# nrf7120_enga_application register map
Vendor: Nordic Semiconductor; Series: nrf71; File version: 1
CPU: CM33 r0p4, little endian, MPU, FPU, 3 interrupt priority bits, 270 interrupts, 4 SAU regions
Registers are 32-bit, read-write, reset 0x0 unless marked. A register's access mark holds for its fields unless they carry their own. Offsets are from the block's base; [hi:lo] are bit positions; lines under a group give offsets from that group; 'fields as' and 'values as' point back to an identical list.

## CPUC_S — CPU control
Base 0xE0080000
0x100 EVENTS_FPUIOC — An invalid operation exception has occurred in the FPU.
  [0] EVENTS_FPUIOC
    0=NotGenerated (Event not generated); 1=Generated (Event generated)
0x104 EVENTS_FPUDZC — A floating-point divide-by-zero exception has occurred in the FPU.
  [0] EVENTS_FPUDZC
    values as EVENTS_FPUIOC.EVENTS_FPUIOC
0x108 EVENTS_FPUOFC — A floating-point overflow exception has occurred in the FPU.
  [0] EVENTS_FPUOFC
    values as EVENTS_FPUIOC.EVENTS_FPUIOC
0x10C EVENTS_FPUUFC — A floating-point underflow exception has occurred in the FPU.
  [0] EVENTS_FPUUFC
    values as EVENTS_FPUIOC.EVENTS_FPUIOC
0x110 EVENTS_FPUIXC — A floating-point inexact exception has occurred in the FPU.
  [0] EVENTS_FPUIXC
    values as EVENTS_FPUIOC.EVENTS_FPUIOC
0x114 EVENTS_FPUIDC — A floating-point input denormal exception has occurred in the FPU.
  [0] EVENTS_FPUIDC
    values as EVENTS_FPUIOC.EVENTS_FPUIOC
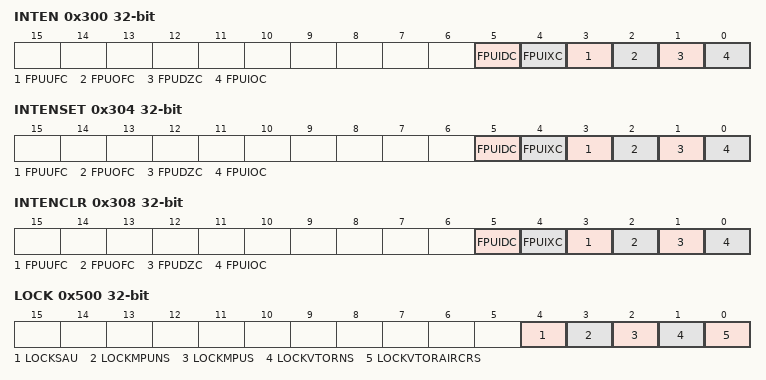
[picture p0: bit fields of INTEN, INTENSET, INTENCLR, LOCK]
0x300 INTEN — Enable or disable interrupt
  [all] fields
    0=Disabled; 1=Enabled
  [5] FPUIDC — Enable or disable interrupt for event FPUIDC
  [4] FPUIXC — Enable or disable interrupt for event FPUIXC
  [3] FPUUFC — Enable or disable interrupt for event FPUUFC
  [2] FPUOFC — Enable or disable interrupt for event FPUOFC
  [1] FPUDZC — Enable or disable interrupt for event FPUDZC
  [0] FPUIOC — Enable or disable interrupt for event FPUIOC
0x304 INTENSET — Enable interrupt
  [all] fields
    on read: 0=Disabled (Read: Disabled); 1=Enabled (Read: Enabled) | on write: 1=Set (Enable)
  [5] FPUIDC — Write '1' to enable interrupt for event FPUIDC
  [4] FPUIXC — Write '1' to enable interrupt for event FPUIXC
  [3] FPUUFC — Write '1' to enable interrupt for event FPUUFC
  [2] FPUOFC — Write '1' to enable interrupt for event FPUOFC
  [1] FPUDZC — Write '1' to enable interrupt for event FPUDZC
  [0] FPUIOC — Write '1' to enable interrupt for event FPUIOC
0x308 INTENCLR — Disable interrupt
  [all] fields
    on read: 0=Disabled (Read: Disabled); 1=Enabled (Read: Enabled) | on write: 1=Clear (Disable)
  [5] FPUIDC — Write '1' to disable interrupt for event FPUIDC
  [4] FPUIXC — Write '1' to disable interrupt for event FPUIXC
  [3] FPUUFC — Write '1' to disable interrupt for event FPUUFC
  [2] FPUOFC — Write '1' to disable interrupt for event FPUOFC
  [1] FPUDZC — Write '1' to disable interrupt for event FPUDZC
  [0] FPUIOC — Write '1' to disable interrupt for event FPUIOC
0x500 LOCK — Register to lock the certain parts of the CPU from being modified.
  [4] LOCKSAU — Locks the Security Attribution Unit (SAU)
    0=NotLocked (SAU registers can be changed.); 1=Locked (Prevents changes to SAU registers.)
  [3] LOCKMPUNS — Locks the Memory Protection Unit (MPU) for non secure mode.
    0=NotLocked (MPU registers can be changed.); 1=Locked (Prevents changes to MPU registers.)
  [2] LOCKMPUS — Locks the Memory Protection Unit (MPU) for secure mode.
    values as LOCKMPUNS
  [1] LOCKVTORNS — Locks the Vector table Offset Register (VTOR) for non-secure mode.
    0=NotLocked (VTOR can be changed.); 1=Locked (Prevents changes to VTOR.)
  [0] LOCKVTORAIRCRS — Locks both the Vector table Offset Register (VTOR) and Application Interrupt and Reset Control Register (AIRCR) for secure mode.
    0=NotLocked (Both VTOR and AIRCR can be changed.); 1=Locked (Prevents changes to both VTOR and AIRCR.)
0x504 CPUID ro — The identifier for the CPU in this subsystem.
  [31:0] CPUID — The CPU identifier.

## ICACHE_S — Cache
Base 0xE0082000
0x08 TASKS_INVALIDATECACHE wo — Invalidate the cache.
  [0] TASKS_INVALIDATECACHE
    1=Trigger task
0x400 STATUS ro — Status of the cache activities.
  [0] READY — Ready status.
    0=Ready (Activity is done and ready for the next activity.); 1=Busy (Activity is in progress.)
0x404 ENABLE — Enable cache.
  [0] ENABLE — Enable cache
    0=Disabled (Disable cache); 1=Enabled (Enable cache)
0x414 PROFILING group — Unspecified
  0x00 ENABLE — Enable the profiling counters.
    [0] ENABLE — Enable the profiling counters
      0=Disable profiling; 1=Enable profiling
  0x04 CLEAR wo — Clear the profiling counters.
    [0] CLEAR — Clearing the profiling counters
      1=Clear the profiling counters
  0x08 HIT ro — The cache hit counter for cache region.
    [31:0] HITS — Number of cache hits
  0x0C MISS ro — The cache miss counter for cache region.
    [31:0] MISSES — Number of cache misses
0x430 DEBUGLOCK rw-once — Lock debug mode.
  [0] DEBUGLOCK — Lock debug mode
    0=Unlocked (Debug mode unlocked); 1=Locked (Debug mode locked. Ignores any other value written.)
